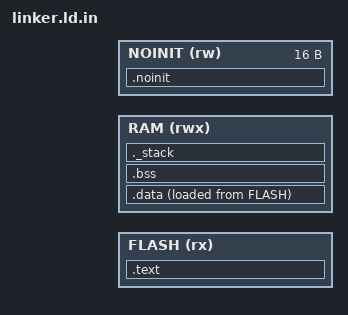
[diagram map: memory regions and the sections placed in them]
/* Preprocessed by the Makefile: FLASH_ORIGIN FLASH_LEN_K RAM_ORIGIN RAM_LEN_K
 * (the two LEN values are in bytes) */
ENTRY(Reset_Handler)

MEMORY
{
    FLASH (rx) : ORIGIN = FLASH_ORIGIN, LENGTH = FLASH_LEN_K
    RAM  (rwx) : ORIGIN = RAM_ORIGIN,   LENGTH = RAM_LEN_K - 16
    /* last 16 bytes of RAM: survive a reset, shared with the serial loader */
    NOINIT (rw) : ORIGIN = RAM_ORIGIN + RAM_LEN_K - 16, LENGTH = 16
}

_estack = ORIGIN(RAM) + LENGTH(RAM);

SECTIONS
{
    .text :
    {
        KEEP(*(.isr_vector))
        *(.text .text.*)
        *(.rodata .rodata.*)
        . = ALIGN(4);
    } > FLASH

    _sidata = LOADADDR(.data);

    .data :
    {
        . = ALIGN(4);
        _sdata = .;
        *(.data .data.*)
        . = ALIGN(4);
        _edata = .;
    } > RAM AT > FLASH

    .bss (NOLOAD) :
    {
        . = ALIGN(4);
        _sbss = .;
        *(.bss .bss.*)
        *(COMMON)
        . = ALIGN(4);
        _ebss = .;
    } > RAM

    /* survives a software reset: the "reboot to boot loader" flag.  bootMagic
     * must stay the ONLY variable here: the serial loader reads it at
     * RAM end - 16 (LD_BOOT_FLAG_ADDR in loader/loader.h). */
    .noinit (NOLOAD) :
    {
        *(.noinit)
    } > NOINIT

    /* keep 1 KB for the stack */
    ._stack (NOLOAD) :
    {
        . = ALIGN(8);
        . = . + 1K;
    } > RAM

    /DISCARD/ :
    {
        *(.ARM.exidx*)
    }
}
